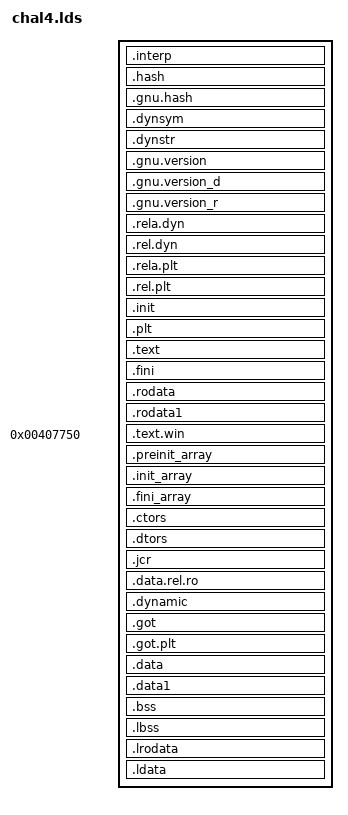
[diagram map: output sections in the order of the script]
ENTRY(_start)
SECTIONS
{
  PROVIDE (__executable_start = SEGMENT_START("text-segment", 0x400000)); . = SEGMENT_START("text-segment", 0x400000) + SIZEOF_HEADERS;
  .interp         : { *(.interp) }
  .hash           : { *(.hash) }
  .gnu.hash       : { *(.gnu.hash) }
  .dynsym         : { *(.dynsym) }
  .dynstr         : { *(.dynstr) }
  .gnu.version    : { *(.gnu.version) }
  .gnu.version_d  : { *(.gnu.version_d) }
  .gnu.version_r  : { *(.gnu.version_r) }
  .rela.dyn       :
    {
      *(.rela.init)
      *(.rela.text .rela.text.*)
      *(.rela.fini)
      *(.rela.rodata .rela.rodata.* .rela.data .rela.data.* .rela.got)
    }
  .rel.dyn       :
    {
      *(.rel.init)
      *(.rel.text .rel.text.*)
      *(.rel.fini)
      *(.rel.rodata .rel.rodata.* .rel.data .rel.data.* .rel.got)
    }
  .rela.plt       : { *(.rela.plt) }
  .rel.plt        : { *(.rel.plt) }
  .init           : { KEEP (*(SORT_NONE(.init))) }
  .plt            : { *(.plt) }
  .text           : { *(.text) *(.text.*) }
  .fini           : { KEEP (*(SORT_NONE(.fini))) }
  .rodata         : { *(.rodata .rodata.* .gnu.linkonce.r.*) }
  .rodata1        : { *(.rodata1) }
  . = 0x407750;
  .text.win       : { *(.win) }
  . = ALIGN (CONSTANT (MAXPAGESIZE)) - ((CONSTANT (MAXPAGESIZE) - .) & (CONSTANT (MAXPAGESIZE) - 1)); . = DATA_SEGMENT_ALIGN (CONSTANT (MAXPAGESIZE), CONSTANT (COMMONPAGESIZE));
  .preinit_array     :
  {
    PROVIDE_HIDDEN (__preinit_array_start = .);
    KEEP (*(.preinit_array))
    PROVIDE_HIDDEN (__preinit_array_end = .);
  }
  .init_array     :
  {
    PROVIDE_HIDDEN (__init_array_start = .);
    KEEP (*(SORT_BY_INIT_PRIORITY(.init_array.*) SORT_BY_INIT_PRIORITY(.ctors.*)))
    KEEP (*(.init_array EXCLUDE_FILE (*crtbegin.o *crtbegin?.o *crtend.o *crtend?.o ) .ctors))
    PROVIDE_HIDDEN (__init_array_end = .);
  }
  .fini_array     :
  {
    PROVIDE_HIDDEN (__fini_array_start = .);
    KEEP (*(SORT_BY_INIT_PRIORITY(.fini_array.*) SORT_BY_INIT_PRIORITY(.dtors.*)))
    KEEP (*(.fini_array EXCLUDE_FILE (*crtbegin.o *crtbegin?.o *crtend.o *crtend?.o ) .dtors))
    PROVIDE_HIDDEN (__fini_array_end = .);
  }
  .ctors          :
  {
    KEEP (*crtbegin.o(.ctors))
    KEEP (*crtbegin?.o(.ctors))
    KEEP (*(EXCLUDE_FILE (*crtend.o *crtend?.o ) .ctors))
    KEEP (*(SORT(.ctors.*)))
    KEEP (*(.ctors))
  }
  .dtors          :
  {
    KEEP (*crtbegin.o(.dtors))
    KEEP (*crtbegin?.o(.dtors))
    KEEP (*(EXCLUDE_FILE (*crtend.o *crtend?.o ) .dtors))
    KEEP (*(SORT(.dtors.*)))
    KEEP (*(.dtors))
  }
  .jcr            : { KEEP (*(.jcr)) }
  .data.rel.ro : { *(.data.rel.ro.local* .gnu.linkonce.d.rel.ro.local.*) *(.data.rel.ro .data.rel.ro.* .gnu.linkonce.d.rel.ro.*) }
  .dynamic        : { *(.dynamic) }
  .got            : { *(.got) *(.igot) }
  . = DATA_SEGMENT_RELRO_END (SIZEOF (.got.plt) >= 24 ? 24 : 0, .);
  .got.plt        : { *(.got.plt)  *(.igot.plt) }
  .data           :
  {
    *(.data .data.* .gnu.linkonce.d.*)
    SORT(CONSTRUCTORS)
  }
  .data1          : { *(.data1) }
  _edata = .; PROVIDE (edata = .);
  . = .;
  __bss_start = .;
  .bss            :
  {
   *(.dynbss)
   *(.bss .bss.* .gnu.linkonce.b.*)
   *(COMMON)
   /* Align here to ensure that the .bss section occupies space up to
      _end.  Align after .bss to ensure correct alignment even if the
      .bss section disappears because there are no input sections.
      FIXME: Why do we need it? When there is no .bss section, we don't
      pad the .data section.  */
   . = ALIGN(. != 0 ? 64 / 8 : 1);
  }
  .lbss   :
  {
    *(.dynlbss)
    *(.lbss .lbss.* .gnu.linkonce.lb.*)
    *(LARGE_COMMON)
  }
  . = ALIGN(64 / 8);
  . = SEGMENT_START("ldata-segment", .);
  .lrodata   ALIGN(CONSTANT (MAXPAGESIZE)) + (. & (CONSTANT (MAXPAGESIZE) - 1)) :
  {
    *(.lrodata .lrodata.* .gnu.linkonce.lr.*)
  }
  .ldata   ALIGN(CONSTANT (MAXPAGESIZE)) + (. & (CONSTANT (MAXPAGESIZE) - 1)) :
  {
    *(.ldata .ldata.* .gnu.linkonce.l.*)
    . = ALIGN(. != 0 ? 64 / 8 : 1);
  }
  . = ALIGN(64 / 8);
  _end = .; PROVIDE (end = .);
  . = DATA_SEGMENT_END (.);
  /DISCARD/ : { *(.eh_frame*) *(.note*) *(.debug_*) *(.comment) *(.note.GNU-stack) *(.gnu_debuglink) *(.gnu.lto_*) }
}
